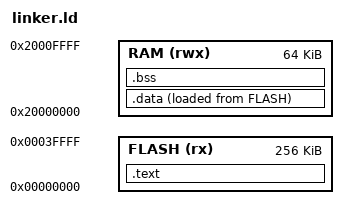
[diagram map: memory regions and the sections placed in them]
/* Memory map matches QEMU's lm3s6965evb (Cortex-M3): 256 KB flash, 64 KB SRAM */
ENTRY(Reset_Handler)

MEMORY
{
  FLASH (rx)  : ORIGIN = 0x00000000, LENGTH = 256K
  RAM   (rwx) : ORIGIN = 0x20000000, LENGTH = 64K
}

_estack = ORIGIN(RAM) + LENGTH(RAM);

SECTIONS
{
  .text :
  {
    KEEP(*(.isr_vector))
    *(.text*)
    *(.rodata*)
    . = ALIGN(4);
  } > FLASH

  _sidata = LOADADDR(.data);

  .data :
  {
    _sdata = .;
    *(.data*)
    . = ALIGN(4);
    _edata = .;
  } > RAM AT> FLASH

  .bss :
  {
    _sbss = .;
    *(.bss*)
    *(COMMON)
    . = ALIGN(4);
    _ebss = .;
  } > RAM

  /DISCARD/ : { *(.ARM.exidx*) *(.ARM.extab*) }
}
